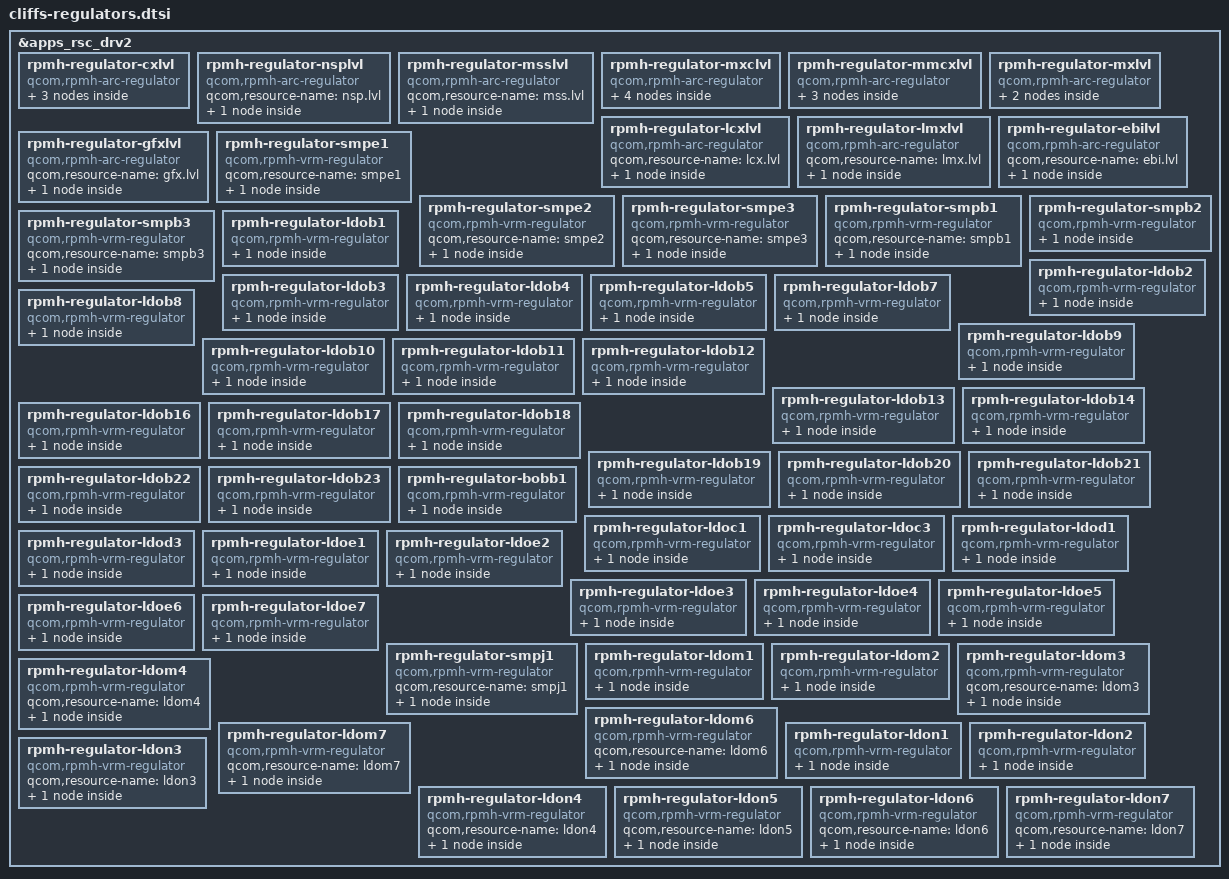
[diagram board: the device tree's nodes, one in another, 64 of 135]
#include <dt-bindings/regulator/qcom,rpmh-regulator-levels.h>

&apps_rsc_drv2 {
	rpmh-regulator-cxlvl {
		compatible = "qcom,rpmh-arc-regulator";
		qcom,resource-name = "cx.lvl";
		proxy-supply = <&VDD_CX_LEVEL>;

		VDD_CX_LEVEL:
		S1C_LEVEL:
		pm_v6c_s1_level: regulator-pm_v6c-s1-level {
			regulator-name = "pm_v6c_s1_level";
			qcom,set = <RPMH_REGULATOR_SET_ALL>;
			regulator-min-microvolt =
				<RPMH_REGULATOR_LEVEL_RETENTION>;
			regulator-max-microvolt = <RPMH_REGULATOR_LEVEL_MAX>;
			qcom,init-voltage-level =
				<RPMH_REGULATOR_LEVEL_TURBO>;
			qcom,proxy-consumer-enable;
			qcom,proxy-consumer-voltage =
				<RPMH_REGULATOR_LEVEL_TURBO
				 RPMH_REGULATOR_LEVEL_MAX>;
		};

		VDD_CX_LEVEL_AO:
		S1C_LEVEL_AO:
		pm_v6c_s1_level_ao: regulator-pm_v6c-s1-level-ao {
			regulator-name = "pm_v6c_s1_level_ao";
			qcom,set = <RPMH_REGULATOR_SET_ACTIVE>;
			regulator-min-microvolt =
				<RPMH_REGULATOR_LEVEL_RETENTION>;
			regulator-max-microvolt = <RPMH_REGULATOR_LEVEL_MAX>;
			qcom,init-voltage-level =
				<RPMH_REGULATOR_LEVEL_RETENTION>;
		};

		VDD_CX_MMCX_SUPPLY_LEVEL: regulator-pm_v6c-s1-mmcx-sup-level {
			regulator-name = "pm_v6c_s1_mmcx_sup_level";
			qcom,set = <RPMH_REGULATOR_SET_ALL>;
			regulator-min-microvolt =
				<RPMH_REGULATOR_LEVEL_MIN_SVS>;
			regulator-max-microvolt =
				<RPMH_REGULATOR_LEVEL_MAX>;
			qcom,init-voltage-level =
				<RPMH_REGULATOR_LEVEL_MIN_SVS>;
		};
	};

	rpmh-regulator-nsplvl {
		compatible = "qcom,rpmh-arc-regulator";
		qcom,resource-name = "nsp.lvl";
		VDD_NSP_LEVEL:
		S2C_LEVEL:
		pm_v6c_s2_level: regulator-pm_v6c-s2-level {
			regulator-name = "pm_v6c_s2_level";
			qcom,set = <RPMH_REGULATOR_SET_ALL>;
			regulator-min-microvolt =
				<RPMH_REGULATOR_LEVEL_RETENTION>;
			regulator-max-microvolt = <RPMH_REGULATOR_LEVEL_MAX>;
			qcom,init-voltage-level =
				<RPMH_REGULATOR_LEVEL_RETENTION>;
		};
	};

	rpmh-regulator-msslvl {
		compatible = "qcom,rpmh-arc-regulator";
		qcom,resource-name = "mss.lvl";
		VDD_MODEM_LEVEL:
		S4C_LEVEL:
		pm_v6c_s4_level: regulator-pm_v6c-s4-level {
			regulator-name = "pm_v6c_s4_level";
			qcom,set = <RPMH_REGULATOR_SET_ALL>;
			regulator-min-microvolt =
				<RPMH_REGULATOR_LEVEL_RETENTION>;
			regulator-max-microvolt = <RPMH_REGULATOR_LEVEL_MAX>;
			qcom,init-voltage-level =
				<RPMH_REGULATOR_LEVEL_RETENTION>;
		};
	};

	rpmh-regulator-mxclvl {
		compatible = "qcom,rpmh-arc-regulator";
		qcom,resource-name = "mxc.lvl";
		proxy-supply = <&VDD_MXC_LEVEL>;

		VDD_MXC_LEVEL:
		S6C_LEVEL:
		pm_v6c_s6_level: regulator-pm_v6c-s6-level {
			regulator-name = "pm_v6c_s6_level";
			qcom,set = <RPMH_REGULATOR_SET_ALL>;
			regulator-min-microvolt =
				<RPMH_REGULATOR_LEVEL_RETENTION>;
			regulator-max-microvolt = <RPMH_REGULATOR_LEVEL_MAX>;
			qcom,init-voltage-level =
				<RPMH_REGULATOR_LEVEL_TURBO>;
			qcom,proxy-consumer-enable;
			qcom,proxy-consumer-voltage =
				<RPMH_REGULATOR_LEVEL_TURBO
				 RPMH_REGULATOR_LEVEL_MAX>;
		};

		VDD_MXC_LEVEL_AO:
		S6C_LEVEL_AO:
		pm_v6c_s6_level_ao: regulator-pm_v6c-s6-level-ao {
			regulator-name = "pm_v6c_s6_level_ao";
			qcom,set = <RPMH_REGULATOR_SET_ACTIVE>;
			regulator-min-microvolt =
				<RPMH_REGULATOR_LEVEL_RETENTION>;
			regulator-max-microvolt = <RPMH_REGULATOR_LEVEL_MAX>;
			qcom,init-voltage-level =
				<RPMH_REGULATOR_LEVEL_RETENTION>;
		};

		VDD_MXC_MMCX_VOTER_LEVEL:
		VDD_MXC_MM_VOTER_LEVEL:
		VDD_MM_MXC_VOTER_LEVEL: regulator-pm_v6c-s6-mmcx-voter-level {
			regulator-name = "pm_v6c_s6_mmcx_voter_level";
			pm_v6c_s6_mmcx_voter_level-parent-supply =
				<&VDD_MMCX_LEVEL>;
			qcom,set = <RPMH_REGULATOR_SET_ALL>;
			regulator-min-microvolt =
				<RPMH_REGULATOR_LEVEL_MIN_SVS>;
			regulator-max-microvolt =
				<RPMH_REGULATOR_LEVEL_MAX>;
			qcom,init-voltage-level =
				<RPMH_REGULATOR_LEVEL_MIN_SVS>;
		};

		VDD_MXC_GFX_VOTER_LEVEL:
		VDD_GFX_MXC_VOTER_LEVEL:
		regulator-pm_v6c-s6-gfx-voter-level {
			regulator-name = "pm_v6c_s6_gfx_voter_level";
			pm_v6c_s6_gfx_voter_level-parent-supply =
				<&VDD_GFX_LEVEL>;
			qcom,set = <RPMH_REGULATOR_SET_ALL>;
			regulator-min-microvolt =
				<RPMH_REGULATOR_LEVEL_MIN_SVS>;
			regulator-max-microvolt =
				<RPMH_REGULATOR_LEVEL_MAX>;
			qcom,init-voltage-level =
				<RPMH_REGULATOR_LEVEL_MIN_SVS>;
		};
	};

	rpmh-regulator-mmcxlvl {
		compatible = "qcom,rpmh-arc-regulator";
		qcom,resource-name = "mmcx.lvl";
		proxy-supply = <&VDD_MMCX_LEVEL>;

		VDD_MMCX_LEVEL:
		VDD_MM_LEVEL:
		S6D_LEVEL:
		pm_v8_s6_level: regulator-pm_v8-s6-level {
			regulator-name = "pm_v8_s6_level";
			qcom,set = <RPMH_REGULATOR_SET_ALL>;
			pm_v8_s6_level-parent-supply =
				<&VDD_CX_MMCX_SUPPLY_LEVEL>;
			regulator-min-microvolt =
				<RPMH_REGULATOR_LEVEL_LOW_SVS_D1>;
			regulator-max-microvolt = <RPMH_REGULATOR_LEVEL_MAX>;
			qcom,init-voltage-level =
				<RPMH_REGULATOR_LEVEL_TURBO>;
			qcom,proxy-consumer-enable;
			qcom,proxy-consumer-voltage =
				<RPMH_REGULATOR_LEVEL_TURBO
				 RPMH_REGULATOR_LEVEL_MAX>;
		};

		VDD_MMCX_LEVEL_AO:
		S6D_LEVEL_AO:
		pm_v8_s6_level_ao: regulator-pm_v8-s6-level-ao {
			regulator-name = "pm_v8_s6_level_ao";
			qcom,set = <RPMH_REGULATOR_SET_ACTIVE>;
			regulator-min-microvolt =
				<RPMH_REGULATOR_LEVEL_LOW_SVS_D1>;
			regulator-max-microvolt = <RPMH_REGULATOR_LEVEL_MAX>;
			qcom,init-voltage-level =
				<RPMH_REGULATOR_LEVEL_LOW_SVS_D1>;
		};

		regulator-pm_v8-s6-level-so {
			regulator-name = "pm_v8_s6_level_so";
			qcom,set = <RPMH_REGULATOR_SET_SLEEP>;
			regulator-min-microvolt =
				<RPMH_REGULATOR_LEVEL_LOW_SVS_D1>;
			regulator-max-microvolt = <RPMH_REGULATOR_LEVEL_MAX>;
			qcom,init-voltage-level =
				<RPMH_REGULATOR_LEVEL_LOW_SVS_D1>;
		};
	};

	rpmh-regulator-mxlvl {
		compatible = "qcom,rpmh-arc-regulator";
		qcom,resource-name = "mx.lvl";
		proxy-supply = <&VDD_MXA_LEVEL>;

		VDD_MXA_LEVEL:
		S8D_LEVEL:
		pm_v8_s8_level: regulator-pm_v8-s8-level {
			regulator-name = "pm_v8_s8_level";
			qcom,set = <RPMH_REGULATOR_SET_ALL>;
			regulator-min-microvolt =
				<RPMH_REGULATOR_LEVEL_RETENTION>;
			regulator-max-microvolt = <RPMH_REGULATOR_LEVEL_MAX>;
			qcom,init-voltage-level =
				<RPMH_REGULATOR_LEVEL_TURBO>;
			qcom,proxy-consumer-enable;
			qcom,proxy-consumer-voltage =
				<RPMH_REGULATOR_LEVEL_TURBO
				 RPMH_REGULATOR_LEVEL_MAX>;
		};

		VDD_MXA_LEVEL_AO:
		S8D_LEVEL_AO:
		pm_v8_s8_level_ao: regulator-pm_v8-s8-level-ao {
			regulator-name = "pm_v8_s8_level_ao";
			qcom,set = <RPMH_REGULATOR_SET_ACTIVE>;
			regulator-min-microvolt =
				<RPMH_REGULATOR_LEVEL_RETENTION>;
			regulator-max-microvolt = <RPMH_REGULATOR_LEVEL_MAX>;
			qcom,init-voltage-level =
				<RPMH_REGULATOR_LEVEL_RETENTION>;
		};
	};

	rpmh-regulator-lcxlvl {
		compatible = "qcom,rpmh-arc-regulator";
		qcom,resource-name = "lcx.lvl";

		VDD_LPI_CX_LEVEL:
		L2D_LEVEL:
		pm_v8_l2_level: regulator-pm_v8-l2-level {
			regulator-name = "pm_v8_l2_level";
			qcom,set = <RPMH_REGULATOR_SET_ALL>;
			regulator-min-microvolt =
				<RPMH_REGULATOR_LEVEL_RETENTION>;
			regulator-max-microvolt = <RPMH_REGULATOR_LEVEL_MAX>;
			qcom,init-voltage-level =
				<RPMH_REGULATOR_LEVEL_RETENTION>;
		};
	};

	rpmh-regulator-lmxlvl {
		compatible = "qcom,rpmh-arc-regulator";
		qcom,resource-name = "lmx.lvl";

		VDD_LPI_MX_LEVEL:
		L2C_LEVEL:
		pm_v6c_l2_level: regulator-pm_v6c-l2-level {
			regulator-name = "pm_v6c_l2_level";
			qcom,set = <RPMH_REGULATOR_SET_ALL>;
			regulator-min-microvolt =
				<RPMH_REGULATOR_LEVEL_RETENTION>;
			regulator-max-microvolt = <RPMH_REGULATOR_LEVEL_MAX>;
			qcom,init-voltage-level =
				<RPMH_REGULATOR_LEVEL_RETENTION>;
		};
	};

	rpmh-regulator-ebilvl {
		compatible = "qcom,rpmh-arc-regulator";
		qcom,resource-name = "ebi.lvl";

		VDD_EBI_LEVEL:
		S1I_LEVEL:
		pmg1110_i_s1_level: regulator-pmg1110-i-s1-level {
			regulator-name = "pmg1110_i_s1_level";
			qcom,set = <RPMH_REGULATOR_SET_ALL>;
			regulator-min-microvolt =
				<RPMH_REGULATOR_LEVEL_RETENTION>;
			regulator-max-microvolt = <RPMH_REGULATOR_LEVEL_MAX>;
			qcom,init-voltage-level =
				<RPMH_REGULATOR_LEVEL_RETENTION>;
		};
	};

	rpmh-regulator-gfxlvl {
		compatible = "qcom,rpmh-arc-regulator";
		qcom,resource-name = "gfx.lvl";

		VDD_GFX_LEVEL:
		S4B_LEVEL:
		pmxr2230_s4_level: regulator-pmxr2230-s4-level {
			regulator-name = "pmxr2230_s4_level";
			qcom,set = <RPMH_REGULATOR_SET_ALL>;
			regulator-min-microvolt =
				<RPMH_REGULATOR_LEVEL_RETENTION>;
			regulator-max-microvolt = <RPMH_REGULATOR_LEVEL_MAX>;
			qcom,init-voltage-level =
				<RPMH_REGULATOR_LEVEL_RETENTION>;
		};
	};

	rpmh-regulator-smpe1 {
		compatible = "qcom,rpmh-vrm-regulator";
		qcom,resource-name = "smpe1";

		S1E:
		pmr735a_s1: regulator-pmr735a-s1 {
			regulator-name = "pmr735a_s1";
			qcom,set = <RPMH_REGULATOR_SET_ALL>;
			regulator-min-microvolt = <1010000>;
			regulator-max-microvolt = <1120000>;
			qcom,init-voltage = <1080000>;
		};
	};

	rpmh-regulator-smpe2 {
		compatible = "qcom,rpmh-vrm-regulator";
		qcom,resource-name = "smpe2";

		S2E:
		pmr735a_s2: regulator-pmr735a-s2 {
			regulator-name = "pmr735a_s2";
			qcom,set = <RPMH_REGULATOR_SET_ALL>;
			regulator-min-microvolt = <300000>;
			regulator-max-microvolt = <570000>;
			qcom,init-voltage = <500000>;
		};
	};

	rpmh-regulator-smpe3 {
		compatible = "qcom,rpmh-vrm-regulator";
		qcom,resource-name = "smpe3";

		S3E:
		pmr735a_s3: regulator-pmr735a-s3 {
			regulator-name = "pmr735a_s3";
			qcom,set = <RPMH_REGULATOR_SET_ALL>;
			regulator-min-microvolt = <1600000>;
			regulator-max-microvolt = <2400000>;
			qcom,init-voltage = <1600000>;
		};
	};

	rpmh-regulator-smpb1 {
		compatible = "qcom,rpmh-vrm-regulator";
		qcom,resource-name = "smpb1";

		S1B:
		pmxr2230_s1: regulator-pmxr2230-s1 {
			regulator-name = "pmxr2230_s1";
			qcom,set = <RPMH_REGULATOR_SET_ALL>;
			regulator-min-microvolt = <1856000>;
			regulator-max-microvolt = <2040000>;
			qcom,init-voltage = <1856000>;
		};
	};

	rpmh-regulator-smpb2 {
		compatible = "qcom,rpmh-vrm-regulator";
		qcom,resource-name = "smpb2";
		qcom,regulator-type = "pmic5-ftsmps";
		qcom,supported-modes = <RPMH_REGULATOR_MODE_RET
			 RPMH_REGULATOR_MODE_HPM>;
		qcom,mode-threshold-currents = <0 200000>;

		S2B:
		pmxr2230_s2: regulator-pmxr2230-s2 {
			regulator-name = "pmxr2230_s2";
			qcom,set = <RPMH_REGULATOR_SET_ALL>;
			regulator-min-microvolt = <1256000>;
			regulator-max-microvolt = <1408000>;
			qcom,init-voltage = <1256000>;
			qcom,init-mode = <RPMH_REGULATOR_MODE_RET>;
		};
	};

	rpmh-regulator-smpb3 {
		compatible = "qcom,rpmh-vrm-regulator";
		qcom,resource-name = "smpb3";

		S3B:
		pmxr2230_s3: regulator-pmxr2230-s3 {
			regulator-name = "pmxr2230_s3";
			qcom,set = <RPMH_REGULATOR_SET_ALL>;
			regulator-min-microvolt = <968000>;
			regulator-max-microvolt = <1040000>;
			qcom,init-voltage = <984000>;
		};
	};

	rpmh-regulator-ldob1 {
		compatible = "qcom,rpmh-vrm-regulator";
		qcom,resource-name = "ldob1";
		qcom,regulator-type = "pmic5-ldo";
		qcom,supported-modes =
			<RPMH_REGULATOR_MODE_LPM
			RPMH_REGULATOR_MODE_HPM>;
		qcom,mode-threshold-currents = <0 30000>;

		L1B:
		pmxr2230_l1: regulator-pmxr2230-l1 {
			regulator-name = "pmxr2230_l1";
			qcom,set = <RPMH_REGULATOR_SET_ALL>;
			regulator-min-microvolt = <880000>;
			regulator-max-microvolt = <958000>;
			qcom,init-voltage = <880000>;
			qcom,init-mode = <RPMH_REGULATOR_MODE_HPM>;
		};
	};

	rpmh-regulator-ldob2 {
		compatible = "qcom,rpmh-vrm-regulator";
		qcom,resource-name = "ldob2";
		qcom,regulator-type = "pmic5-ldo";
		qcom,supported-modes =
			<RPMH_REGULATOR_MODE_LPM
			RPMH_REGULATOR_MODE_HPM>;
		qcom,mode-threshold-currents = <0 30000>;
		proxy-supply = <&pmxr2230_l2>;

		L2B:
		pmxr2230_l2: regulator-pmxr2230-l2 {
			regulator-name = "pmxr2230_l2";
			qcom,set = <RPMH_REGULATOR_SET_ALL>;
			regulator-min-microvolt = <880000>;
			regulator-max-microvolt = <950000>;
			qcom,init-voltage = <880000>;
			qcom,init-mode = <RPMH_REGULATOR_MODE_HPM>;
			qcom,proxy-consumer-enable;
			qcom,supply-enable-load = <98000>;
		};
	};

	rpmh-regulator-ldob3 {
		compatible = "qcom,rpmh-vrm-regulator";
		qcom,resource-name = "ldob3";
		qcom,regulator-type = "pmic5-ldo";
		qcom,supported-modes =
			<RPMH_REGULATOR_MODE_LPM
			RPMH_REGULATOR_MODE_HPM>;
		qcom,mode-threshold-currents = <0 30000>;

		L3B:
		pmxr2230_l3: regulator-pmxr2230-l3 {
			regulator-name = "pmxr2230_l3";
			qcom,set = <RPMH_REGULATOR_SET_ALL>;
			regulator-min-microvolt = <880000>;
			regulator-max-microvolt = <920000>;
			qcom,init-voltage = <880000>;
			qcom,init-mode = <RPMH_REGULATOR_MODE_HPM>;
		};
	};

	rpmh-regulator-ldob4 {
		compatible = "qcom,rpmh-vrm-regulator";
		qcom,resource-name = "ldob4";
		qcom,regulator-type = "pmic5-ldo";
		qcom,supported-modes =
			<RPMH_REGULATOR_MODE_LPM
			RPMH_REGULATOR_MODE_HPM>;
		qcom,mode-threshold-currents = <0 30000>;
		proxy-supply = <&pmxr2230_l4>;

		L4B:
		pmxr2230_l4: regulator-pmxr2230-l4 {
			regulator-name = "pmxr2230_l4";
			qcom,set = <RPMH_REGULATOR_SET_ALL>;
			regulator-min-microvolt = <1200000>;
			regulator-max-microvolt = <1200000>;
			qcom,init-voltage = <1200000>;
			qcom,init-mode = <RPMH_REGULATOR_MODE_HPM>;
			qcom,proxy-consumer-enable;
			qcom,supply-enable-load = <16600>;
		};
	};

	rpmh-regulator-ldob5 {
		compatible = "qcom,rpmh-vrm-regulator";
		qcom,resource-name = "ldob5";
		qcom,regulator-type = "pmic5-ldo";
		qcom,supported-modes =
			<RPMH_REGULATOR_MODE_RET
			RPMH_REGULATOR_MODE_LPM
			RPMH_REGULATOR_MODE_HPM>;
		qcom,mode-threshold-currents = <0 10000 30000>;

		L5B:
		pmxr2230_l5: regulator-pmxr2230-l5 {
			regulator-name = "pmxr2230_l5";
			qcom,set = <RPMH_REGULATOR_SET_ALL>;
			regulator-min-microvolt = <1200000>;
			regulator-max-microvolt = <1200000>;
			qcom,init-voltage = <1200000>;
			qcom,init-mode = <RPMH_REGULATOR_MODE_HPM>;
		};
	};

	rpmh-regulator-ldob7 {
		compatible = "qcom,rpmh-vrm-regulator";
		qcom,resource-name = "ldob7";
		qcom,regulator-type = "pmic5-ldo";
		qcom,supported-modes =
			<RPMH_REGULATOR_MODE_LPM
			RPMH_REGULATOR_MODE_HPM>;
		qcom,mode-threshold-currents = <0 30000>;

		L7B:
		pmxr2230_l7: regulator-pmxr2230-l7 {
			regulator-name = "pmxr2230_l7";
			qcom,set = <RPMH_REGULATOR_SET_ALL>;
			regulator-min-microvolt = <1800000>;
			regulator-max-microvolt = <1800000>;
			qcom,init-voltage = <1800000>;
			qcom,init-mode = <RPMH_REGULATOR_MODE_HPM>;
		};
	};

	rpmh-regulator-ldob8 {
		compatible = "qcom,rpmh-vrm-regulator";
		qcom,resource-name = "ldob8";
		qcom,regulator-type = "pmic5-ldo";
		qcom,supported-modes =
			<RPMH_REGULATOR_MODE_LPM
			RPMH_REGULATOR_MODE_HPM>;
		qcom,mode-threshold-currents = <0 30000>;
		proxy-supply = <&pmxr2230_l8>;

		L8B:
		pmxr2230_l8: regulator-pmxr2230-l8 {
			regulator-name = "pmxr2230_l8";
			qcom,set = <RPMH_REGULATOR_SET_ALL>;
			regulator-min-microvolt = <1800000>;
			regulator-max-microvolt = <1800000>;
			qcom,init-voltage = <1800000>;
			qcom,init-mode = <RPMH_REGULATOR_MODE_HPM>;
			qcom,proxy-consumer-enable;
			qcom,proxy-consumer-current = <220000>;
		};
	};

	rpmh-regulator-ldob9 {
		compatible = "qcom,rpmh-vrm-regulator";
		qcom,resource-name = "ldob9";
		qcom,regulator-type = "pmic5-ldo";
		qcom,supported-modes =
			<RPMH_REGULATOR_MODE_LPM
			RPMH_REGULATOR_MODE_HPM>;
		qcom,mode-threshold-currents = <0 30000>;

		L9B:
		pmxr2230_l9: regulator-pmxr2230-l9 {
			regulator-name = "pmxr2230_l9";
			qcom,set = <RPMH_REGULATOR_SET_ALL>;
			regulator-min-microvolt = <756000>;
			regulator-max-microvolt = <816000>;
			qcom,init-voltage = <756000>;
			qcom,init-mode = <RPMH_REGULATOR_MODE_HPM>;
		};
	};

	rpmh-regulator-ldob10 {
		compatible = "qcom,rpmh-vrm-regulator";
		qcom,resource-name = "ldob10";
		qcom,regulator-type = "pmic5-ldo";
		qcom,supported-modes =
			<RPMH_REGULATOR_MODE_LPM
			RPMH_REGULATOR_MODE_HPM>;
		qcom,mode-threshold-currents = <0 30000>;

		L10B:
		pmxr2230_l10: regulator-pmxr2230-l10 {
			regulator-name = "pmxr2230_l10";
			qcom,set = <RPMH_REGULATOR_SET_ALL>;
			regulator-min-microvolt = <866000>;
			regulator-max-microvolt = <931000>;
			qcom,init-voltage = <866000>;
			qcom,init-mode = <RPMH_REGULATOR_MODE_HPM>;
		};
	};

	rpmh-regulator-ldob11 {
		compatible = "qcom,rpmh-vrm-regulator";
		qcom,resource-name = "ldob11";
		qcom,regulator-type = "pmic5-ldo";
		qcom,supported-modes =
			<RPMH_REGULATOR_MODE_LPM
			RPMH_REGULATOR_MODE_HPM>;
		qcom,mode-threshold-currents = <0 30000>;

		L11B:
		pmxr2230_l11: regulator-pmxr2230-l11 {
			regulator-name = "pmxr2230_l11";
			qcom,set = <RPMH_REGULATOR_SET_ALL>;
			regulator-min-microvolt = <1800000>;
			regulator-max-microvolt = <1800000>;
			qcom,init-voltage = <1800000>;
			qcom,init-mode = <RPMH_REGULATOR_MODE_HPM>;
		};
	};

	rpmh-regulator-ldob12 {
		compatible = "qcom,rpmh-vrm-regulator";
		qcom,resource-name = "ldob12";
		qcom,regulator-type = "pmic5-ldo";
		qcom,supported-modes =
			<RPMH_REGULATOR_MODE_LPM
			RPMH_REGULATOR_MODE_HPM>;
		qcom,mode-threshold-currents = <0 10000>;

		L12B:
		pmxr2230_l12: regulator-pmxr2230-l12 {
			regulator-name = "pmxr2230_l12";
			qcom,set = <RPMH_REGULATOR_SET_ALL>;
			qcom,init-mode = <RPMH_REGULATOR_MODE_HPM>;
			/*
			 * Remove min/max voltages for this regulator as initial
			 * voltage of  L12B is set to be 2.4v/2.96v during PON
			 * depending upon the UFS mode. UFS is the only client
			 * on this and this regulator will only be voted
			 * for enabling/disabling conditions.
			 */
		};
	};

	rpmh-regulator-ldob13 {
		compatible = "qcom,rpmh-vrm-regulator";
		qcom,resource-name = "ldob13";
		qcom,regulator-type = "pmic5-ldo";
		qcom,supported-modes =
			<RPMH_REGULATOR_MODE_LPM
			RPMH_REGULATOR_MODE_HPM>;
		qcom,mode-threshold-currents = <0 10000>;

		L13B:
		pmxr2230_l13: regulator-pmxr2230-l13 {
			regulator-name = "pmxr2230_l13";
			qcom,set = <RPMH_REGULATOR_SET_ALL>;
			regulator-min-microvolt = <2700000>;
			regulator-max-microvolt = <3300000>;
			qcom,init-voltage = <2700000>;
			qcom,init-mode = <RPMH_REGULATOR_MODE_HPM>;
		};
	};

	rpmh-regulator-ldob14 {
		compatible = "qcom,rpmh-vrm-regulator";
		qcom,resource-name = "ldob14";
		qcom,regulator-type = "pmic5-ldo";
		qcom,supported-modes =
			<RPMH_REGULATOR_MODE_LPM
			RPMH_REGULATOR_MODE_HPM>;
		qcom,mode-threshold-currents = <0 10000>;

		L14B:
		pmxr2230_l14: regulator-pmxr2230-l14 {
			regulator-name = "pmxr2230_l14";
			qcom,set = <RPMH_REGULATOR_SET_ALL>;
			regulator-min-microvolt = <2700000>;
			regulator-max-microvolt = <3300000>;
			qcom,init-voltage = <2700000>;
			qcom,init-mode = <RPMH_REGULATOR_MODE_HPM>;
		};
	};

	rpmh-regulator-ldob16 {
		compatible = "qcom,rpmh-vrm-regulator";
		qcom,resource-name = "ldob16";
		qcom,regulator-type = "pmic5-ldo";
		qcom,supported-modes =
			<RPMH_REGULATOR_MODE_LPM
			RPMH_REGULATOR_MODE_HPM>;
		qcom,mode-threshold-currents = <0 10000>;

		L16B:
		pmxr2230_l16: regulator-pmxr2230-l16 {
			regulator-name = "pmxr2230_l16";
			qcom,set = <RPMH_REGULATOR_SET_ALL>;
			regulator-min-microvolt = <2900000>;
			regulator-max-microvolt = <3544000>;
			qcom,init-voltage = <2900000>;
			qcom,init-mode = <RPMH_REGULATOR_MODE_HPM>;
		};
	};

	rpmh-regulator-ldob17 {
		compatible = "qcom,rpmh-vrm-regulator";
		qcom,resource-name = "ldob17";
		qcom,regulator-type = "pmic5-ldo";
		qcom,supported-modes =
			<RPMH_REGULATOR_MODE_LPM
			RPMH_REGULATOR_MODE_HPM>;
		qcom,mode-threshold-currents = <0 10000>;

		L17B:
		pmxr2230_l17: regulator-pmxr2230-l17 {
			regulator-name = "pmxr2230_l17";
			qcom,set = <RPMH_REGULATOR_SET_ALL>;
			regulator-min-microvolt = <2700000>;
			regulator-max-microvolt = <3300000>;
			qcom,init-voltage = <3104000>;
			qcom,init-mode = <RPMH_REGULATOR_MODE_HPM>;
		};
	};

	rpmh-regulator-ldob18 {
		compatible = "qcom,rpmh-vrm-regulator";
		qcom,resource-name = "ldob18";
		qcom,regulator-type = "pmic5-ldo";
		qcom,supported-modes =
			<RPMH_REGULATOR_MODE_LPM
			RPMH_REGULATOR_MODE_HPM>;
		qcom,mode-threshold-currents = <0 10000>;

		L18B:
		pmxr2230_l18: regulator-pmxr2230-l18 {
			regulator-name = "pmxr2230_l18";
			qcom,set = <RPMH_REGULATOR_SET_ALL>;
			regulator-min-microvolt = <2000000>;
			regulator-max-microvolt = <3000000>;
			qcom,init-voltage = <2000000>;
			qcom,init-mode = <RPMH_REGULATOR_MODE_HPM>;
		};
	};

	rpmh-regulator-ldob19 {
		compatible = "qcom,rpmh-vrm-regulator";
		qcom,resource-name = "ldob19";
		qcom,regulator-type = "pmic5-ldo";
		qcom,supported-modes =
			<RPMH_REGULATOR_MODE_LPM
			RPMH_REGULATOR_MODE_HPM>;
		qcom,mode-threshold-currents = <0 10000>;
		proxy-supply = <&pmxr2230_l19>;

		L19B:
		pmxr2230_l19: regulator-pmxr2230-l19 {
			regulator-name = "pmxr2230_l19";
			qcom,set = <RPMH_REGULATOR_SET_ALL>;
			regulator-min-microvolt = <2600000>;
			regulator-max-microvolt = <3544000>;
			qcom,init-voltage = <2600000>;
			qcom,init-mode = <RPMH_REGULATOR_MODE_HPM>;
			qcom,proxy-consumer-enable;
			qcom,proxy-consumer-current = <10000>;

		};
	};

	rpmh-regulator-ldob20 {
		compatible = "qcom,rpmh-vrm-regulator";
		qcom,resource-name = "ldob20";
		qcom,regulator-type = "pmic5-ldo";
		qcom,supported-modes =
			<RPMH_REGULATOR_MODE_LPM
			RPMH_REGULATOR_MODE_HPM>;
		qcom,mode-threshold-currents = <0 10000>;

		L20B:
		pmxr2230_l20: regulator-pmxr2230-l20 {
			regulator-name = "pmxr2230_l20";
			qcom,set = <RPMH_REGULATOR_SET_ALL>;
			regulator-min-microvolt = <1620000>;
			regulator-max-microvolt = <3544000>;
			qcom,init-voltage = <1620000>;
			qcom,init-mode = <RPMH_REGULATOR_MODE_HPM>;
		};
	};

	rpmh-regulator-ldob21 {
		compatible = "qcom,rpmh-vrm-regulator";
		qcom,resource-name = "ldob21";
		qcom,regulator-type = "pmic5-ldo";
		qcom,supported-modes =
			<RPMH_REGULATOR_MODE_LPM
			RPMH_REGULATOR_MODE_HPM>;
		qcom,mode-threshold-currents = <0 10000>;

		L21B:
		pmxr2230_l21: regulator-pmxr2230-l21 {
			regulator-name = "pmxr2230_l21";
			qcom,set = <RPMH_REGULATOR_SET_ALL>;
			regulator-min-microvolt = <1620000>;
			regulator-max-microvolt = <3544000>;
			qcom,init-voltage = <1620000>;
			qcom,init-mode = <RPMH_REGULATOR_MODE_HPM>;
		};
	};

	rpmh-regulator-ldob22 {
		compatible = "qcom,rpmh-vrm-regulator";
		qcom,resource-name = "ldob22";
		qcom,regulator-type = "pmic5-ldo";
		qcom,supported-modes =
			<RPMH_REGULATOR_MODE_LPM
			RPMH_REGULATOR_MODE_HPM>;
		qcom,mode-threshold-currents = <0 10000>;

		L22B:
		pmxr2230_l22: regulator-pmxr2230-l22 {
			regulator-name = "pmxr2230_l22";
			qcom,set = <RPMH_REGULATOR_SET_ALL>;
			regulator-min-microvolt = <2700000>;
			regulator-max-microvolt = <3400000>;
			qcom,init-voltage = <2700000>;
			qcom,init-mode = <RPMH_REGULATOR_MODE_HPM>;
		};
	};

	rpmh-regulator-ldob23 {
		compatible = "qcom,rpmh-vrm-regulator";
		qcom,resource-name = "ldob23";
		qcom,regulator-type = "pmic5-ldo";
		qcom,supported-modes =
			<RPMH_REGULATOR_MODE_LPM
			RPMH_REGULATOR_MODE_HPM>;
		qcom,mode-threshold-currents = <0 10000>;

		L23B:
		pmxr2230_l23: regulator-pmxr2230-l23 {
			regulator-name = "pmxr2230_l23";
			qcom,set = <RPMH_REGULATOR_SET_ALL>;
			regulator-min-microvolt = <1650000>;
			regulator-max-microvolt = <3544000>;
			qcom,init-voltage = <1650000>;
			qcom,init-mode = <RPMH_REGULATOR_MODE_HPM>;
		};
	};

	rpmh-regulator-bobb1 {
		compatible = "qcom,rpmh-vrm-regulator";
		qcom,resource-name = "bobb1";
		qcom,regulator-type = "pmic5-bob";
		qcom,supported-modes =
			<RPMH_REGULATOR_MODE_PASS
			RPMH_REGULATOR_MODE_AUTO
			RPMH_REGULATOR_MODE_HPM>;
		qcom,mode-threshold-currents = <0 1000000 2000000>;

		BOB:
		pmxr2230_bob: regulator-pmxr2230-bob1 {
			regulator-name = "pmxr2230_bob";
			qcom,set = <RPMH_REGULATOR_SET_ALL>;
			regulator-min-microvolt = <3008000>;
			regulator-max-microvolt = <3960000>;
			qcom,init-voltage = <3296000>;
			qcom,init-mode = <RPMH_REGULATOR_MODE_PASS>;
		};
	};

	rpmh-regulator-ldoc1 {
		compatible = "qcom,rpmh-vrm-regulator";
		qcom,resource-name = "ldoc1";
		qcom,regulator-type = "pmic5-ldo";
		qcom,supported-modes =
			<RPMH_REGULATOR_MODE_LPM
			RPMH_REGULATOR_MODE_HPM>;
		qcom,mode-threshold-currents = <0 30000>;

		L1C:
		pm_v6c_l1: regulator-pm_v6c-l1 {
			regulator-name = "pm_v6c_l1";
			qcom,set = <RPMH_REGULATOR_SET_ALL>;
			regulator-min-microvolt = <904000>;
			regulator-max-microvolt = <970000>;
			qcom,init-voltage = <904000>;
			qcom,init-mode = <RPMH_REGULATOR_MODE_HPM>;
		};
	};

	rpmh-regulator-ldoc3 {
		compatible = "qcom,rpmh-vrm-regulator";
		qcom,resource-name = "ldoc3";
		qcom,regulator-type = "pmic5-ldo";
		qcom,supported-modes =
			<RPMH_REGULATOR_MODE_LPM
			RPMH_REGULATOR_MODE_HPM>;
		qcom,mode-threshold-currents = <0 30000>;
		proxy-supply = <&pm_v6c_l3>;

		L3C:
		pm_v6c_l3: regulator-pm_v6c-l3 {
			regulator-name = "pm_v6c_l3";
			qcom,set = <RPMH_REGULATOR_SET_ALL>;
			regulator-min-microvolt = <1200000>;
			regulator-max-microvolt = <1250000>;
			qcom,init-voltage = <1200000>;
			qcom,init-mode = <RPMH_REGULATOR_MODE_HPM>;
			qcom,proxy-consumer-enable;
			qcom,proxy-consumer-current = <200000>;
		};
	};

	rpmh-regulator-ldod1 {
		compatible = "qcom,rpmh-vrm-regulator";
		qcom,resource-name = "ldod1";
		qcom,regulator-type = "pmic5-ldo";
		qcom,supported-modes =
			<RPMH_REGULATOR_MODE_LPM
			RPMH_REGULATOR_MODE_HPM>;
		qcom,mode-threshold-currents = <0 30000>;

		L1D:
		pm_v8_l1: regulator-pm_v8-l1 {
			regulator-name = "pm_v8_l1";
			qcom,set = <RPMH_REGULATOR_SET_ALL>;
			regulator-min-microvolt = <866000>;
			regulator-max-microvolt = <958000>;
			qcom,init-voltage = <912000>;
			qcom,init-mode = <RPMH_REGULATOR_MODE_HPM>;
		};
	};

	rpmh-regulator-ldod3 {
		compatible = "qcom,rpmh-vrm-regulator";
		qcom,resource-name = "ldod3";
		qcom,regulator-type = "pmic5-ldo";
		qcom,supported-modes =
			<RPMH_REGULATOR_MODE_LPM
			RPMH_REGULATOR_MODE_HPM>;
		qcom,mode-threshold-currents = <0 30000>;
		proxy-supply = <&pm_v8_l3>;

		L3D:
		pm_v8_l3: regulator-pm_v8-l3 {
			regulator-name = "pm_v8_l3";
			qcom,set = <RPMH_REGULATOR_SET_ALL>;
			regulator-min-microvolt = <1140000>;
			regulator-max-microvolt = <1260000>;
			qcom,init-voltage = <1200000>;
			qcom,init-mode = <RPMH_REGULATOR_MODE_HPM>;
			qcom,proxy-consumer-enable;
			qcom,proxy-consumer-current = <31000>;
		};
	};

	rpmh-regulator-ldoe1 {
		compatible = "qcom,rpmh-vrm-regulator";
		qcom,resource-name = "ldoe1";
		qcom,regulator-type = "pmic5-ldo";
		qcom,supported-modes =
			<RPMH_REGULATOR_MODE_LPM
			RPMH_REGULATOR_MODE_HPM>;
		qcom,mode-threshold-currents = <0 30000>;

		L1E:
		pmr735a_l1: regulator-pmr735a-l1 {
			regulator-name = "pmr735a_l1";
			qcom,set = <RPMH_REGULATOR_SET_ALL>;
			regulator-min-microvolt = <488000>;
			regulator-max-microvolt = <912000>;
			qcom,init-voltage = <488000>;
			qcom,init-mode = <RPMH_REGULATOR_MODE_HPM>;
		};
	};

	rpmh-regulator-ldoe2 {
		compatible = "qcom,rpmh-vrm-regulator";
		qcom,resource-name = "ldoe2";
		qcom,regulator-type = "pmic5-ldo";
		qcom,supported-modes =
			<RPMH_REGULATOR_MODE_LPM
			RPMH_REGULATOR_MODE_HPM>;
		qcom,mode-threshold-currents = <0 30000>;

		L2E:
		pmr735a_l2: regulator-pmr735a-l2 {
			regulator-name = "pmr735a_l2";
			qcom,set = <RPMH_REGULATOR_SET_ALL>;
			regulator-min-microvolt = <920000>;
			regulator-max-microvolt = <969000>;
			qcom,init-voltage = <920000>;
			qcom,init-mode = <RPMH_REGULATOR_MODE_HPM>;
		};
	};

	rpmh-regulator-ldoe3 {
		compatible = "qcom,rpmh-vrm-regulator";
		qcom,resource-name = "ldoe3";
		qcom,regulator-type = "pmic5-ldo";
		qcom,supported-modes =
			<RPMH_REGULATOR_MODE_LPM
			RPMH_REGULATOR_MODE_HPM>;
		qcom,mode-threshold-currents = <0 30000>;

		L3E:
		pmr735a_l3: regulator-pmr735a-l3 {
			regulator-name = "pmr735a_l3";
			qcom,set = <RPMH_REGULATOR_SET_ALL>;
			regulator-min-microvolt = <504000>;
			regulator-max-microvolt = <868000>;
			qcom,init-voltage = <504000>;
			qcom,init-mode = <RPMH_REGULATOR_MODE_HPM>;
		};
	};

	rpmh-regulator-ldoe4 {
		compatible = "qcom,rpmh-vrm-regulator";
		qcom,resource-name = "ldoe4";
		qcom,regulator-type = "pmic5-ldo";
		qcom,supported-modes =
			<RPMH_REGULATOR_MODE_LPM
			RPMH_REGULATOR_MODE_HPM>;
		qcom,mode-threshold-currents = <0 10000>;

		L4E:
		pmr735a_l4: regulator-pmr735a-l4 {
			regulator-name = "pmr735a_l4";
			qcom,set = <RPMH_REGULATOR_SET_ALL>;
			regulator-min-microvolt = <1620000>;
			regulator-max-microvolt = <2000000>;
			qcom,init-voltage = <1620000>;
			qcom,init-mode = <RPMH_REGULATOR_MODE_HPM>;
		};
	};

	rpmh-regulator-ldoe5 {
		compatible = "qcom,rpmh-vrm-regulator";
		qcom,resource-name = "ldoe5";
		qcom,regulator-type = "pmic5-ldo";
		qcom,supported-modes =
			<RPMH_REGULATOR_MODE_LPM
			RPMH_REGULATOR_MODE_HPM>;
		qcom,mode-threshold-currents = <0 30000>;

		L5E:
		pmr735a_l5: regulator-pmr735a-l5 {
			regulator-name = "pmr735a_l5";
			qcom,set = <RPMH_REGULATOR_SET_ALL>;
			regulator-min-microvolt = <1100000>;
			regulator-max-microvolt = <1304000>;
			qcom,init-voltage = <1200000>;
			qcom,init-mode = <RPMH_REGULATOR_MODE_HPM>;
		};
	};

	rpmh-regulator-ldoe6 {
		compatible = "qcom,rpmh-vrm-regulator";
		qcom,resource-name = "ldoe6";
		qcom,regulator-type = "pmic5-ldo";
		qcom,supported-modes =
			<RPMH_REGULATOR_MODE_LPM
			RPMH_REGULATOR_MODE_HPM>;
		qcom,mode-threshold-currents = <0 30000>;

		L6E:
		pmr735a_l6: regulator-pmr735a-l6 {
			regulator-name = "pmr735a_l6";
			qcom,set = <RPMH_REGULATOR_SET_ALL>;
			regulator-min-microvolt = <1080000>;
			regulator-max-microvolt = <1304000>;
			qcom,init-voltage = <1080000>;
			qcom,init-mode = <RPMH_REGULATOR_MODE_HPM>;
		};
	};

	rpmh-regulator-ldoe7 {
		compatible = "qcom,rpmh-vrm-regulator";
		qcom,resource-name = "ldoe7";
		qcom,regulator-type = "pmic5-ldo";
		qcom,supported-modes =
			<RPMH_REGULATOR_MODE_LPM
			RPMH_REGULATOR_MODE_HPM>;
		qcom,mode-threshold-currents = <0 10000>;

		L7E:
		pmr735a_l7: regulator-pmr735a-l7 {
			regulator-name = "pmr735a_l7";
			qcom,set = <RPMH_REGULATOR_SET_ALL>;
			regulator-min-microvolt = <1620000>;
			regulator-max-microvolt = <3300000>;
			qcom,init-voltage = <1620000>;
			qcom,init-mode = <RPMH_REGULATOR_MODE_HPM>;
		};
	};

	rpmh-regulator-smpj1 {
		compatible = "qcom,rpmh-vrm-regulator";
		qcom,resource-name = "smpj1";

		S1J:
		pmg1110_j_s1: regulator-pmg1110-j-s1 {
			regulator-name = "pmg1110_j_s1";
			qcom,set = <RPMH_REGULATOR_SET_ALL>;
			regulator-min-microvolt = <504000>;
			regulator-max-microvolt = <868000>;
			qcom,init-voltage = <504000>;
		};
	};

	rpmh-regulator-ldom1 {
		compatible = "qcom,rpmh-vrm-regulator";
		qcom,resource-name = "ldom1";
		qcom,regulator-type = "pmic5-ldo";
		qcom,supported-modes =
			<RPMH_REGULATOR_MODE_LPM
			RPMH_REGULATOR_MODE_HPM>;
		qcom,mode-threshold-currents = <0 30000>;

		L1M:
		pm8010m_l1: regulator-pm8010m-l1 {
			regulator-name = "pm8010m_l1";
			qcom,set = <RPMH_REGULATOR_SET_ALL>;
			regulator-min-microvolt = <1104000>;
			regulator-max-microvolt = <1104000>;
			qcom,init-voltage = <1104000>;
			qcom,init-mode = <RPMH_REGULATOR_MODE_HPM>;
		};
	};

	rpmh-regulator-ldom2 {
		compatible = "qcom,rpmh-vrm-regulator";
		qcom,resource-name = "ldom2";
		qcom,regulator-type = "pmic5-ldo";
		qcom,supported-modes =
			<RPMH_REGULATOR_MODE_LPM
			RPMH_REGULATOR_MODE_HPM>;
		qcom,mode-threshold-currents = <0 30000>;

		L2M:
		pm8010m_l2: regulator-pm8010m-l2 {
			regulator-name = "pm8010m_l2";
			qcom,set = <RPMH_REGULATOR_SET_ALL>;
			regulator-min-microvolt = <1056000>;
			regulator-max-microvolt = <1056000>;
			qcom,init-voltage = <1056000>;
			qcom,init-mode = <RPMH_REGULATOR_MODE_HPM>;
		};
	};

	rpmh-regulator-ldom3 {
		compatible = "qcom,rpmh-vrm-regulator";
		qcom,resource-name = "ldom3";

		L3M:
		pm8010m_l3: regulator-pm8010m-l3 {
			regulator-name = "pm8010m_l3";
			qcom,set = <RPMH_REGULATOR_SET_ALL>;
			regulator-min-microvolt = <2800000>;
			regulator-max-microvolt = <2800000>;
			qcom,init-voltage = <2800000>;
		};
	};

	rpmh-regulator-ldom4 {
		compatible = "qcom,rpmh-vrm-regulator";
		qcom,resource-name = "ldom4";

		L4M:
		pm8010m_l4: regulator-pm8010m-l4 {
			regulator-name = "pm8010m_l4";
			qcom,set = <RPMH_REGULATOR_SET_ALL>;
			regulator-min-microvolt = <2800000>;
			regulator-max-microvolt = <2800000>;
			qcom,init-voltage = <2800000>;
		};
	};

	rpmh-regulator-ldom6 {
		compatible = "qcom,rpmh-vrm-regulator";
		qcom,resource-name = "ldom6";

		L6M:
		pm8010m_l6: regulator-pm8010m-l6 {
			regulator-name = "pm8010m_l6";
			qcom,set = <RPMH_REGULATOR_SET_ALL>;
			regulator-min-microvolt = <2800000>;
			regulator-max-microvolt = <2800000>;
			qcom,init-voltage = <2800000>;
		};
	};

	rpmh-regulator-ldom7 {
		compatible = "qcom,rpmh-vrm-regulator";
		qcom,resource-name = "ldom7";

		L7M:
		pm8010m_l7: regulator-pm8010m-l7 {
			regulator-name = "pm8010m_l7";
			qcom,set = <RPMH_REGULATOR_SET_ALL>;
			regulator-min-microvolt = <2800000>;
			regulator-max-microvolt = <2800000>;
			qcom,init-voltage = <2800000>;
		};
	};

	rpmh-regulator-ldon1 {
		compatible = "qcom,rpmh-vrm-regulator";
		qcom,resource-name = "ldon1";
		qcom,regulator-type = "pmic5-ldo";
		qcom,supported-modes =
			<RPMH_REGULATOR_MODE_LPM
			RPMH_REGULATOR_MODE_HPM>;
		qcom,mode-threshold-currents = <0 30000>;

		L1N:
		pm8010n_l1: regulator-pm8010n-l1 {
			regulator-name = "pm8010n_l1";
			qcom,set = <RPMH_REGULATOR_SET_ALL>;
			regulator-min-microvolt = <1104000>;
			regulator-max-microvolt = <1104000>;
			qcom,init-voltage = <1104000>;
			qcom,init-mode = <RPMH_REGULATOR_MODE_HPM>;
		};
	};

	rpmh-regulator-ldon2 {
		compatible = "qcom,rpmh-vrm-regulator";
		qcom,resource-name = "ldon2";
		qcom,regulator-type = "pmic5-ldo";
		qcom,supported-modes =
			<RPMH_REGULATOR_MODE_LPM
			RPMH_REGULATOR_MODE_HPM>;
		qcom,mode-threshold-currents = <0 30000>;

		L2N:
		pm8010n_l2: regulator-pm8010n-l2 {
			regulator-name = "pm8010n_l2";
			qcom,set = <RPMH_REGULATOR_SET_ALL>;
			regulator-min-microvolt = <1056000>;
			regulator-max-microvolt = <1056000>;
			qcom,init-voltage = <1056000>;
			qcom,init-mode = <RPMH_REGULATOR_MODE_HPM>;
		};
	};

	rpmh-regulator-ldon3 {
		compatible = "qcom,rpmh-vrm-regulator";
		qcom,resource-name = "ldon3";

		L3N:
		pm8010n_l3: regulator-pm8010n-l3 {
			regulator-name = "pm8010n_l3";
			qcom,set = <RPMH_REGULATOR_SET_ALL>;
			regulator-min-microvolt = <1800000>;
			regulator-max-microvolt = <1800000>;
			qcom,init-voltage = <1800000>;
		};
	};

	rpmh-regulator-ldon4 {
		compatible = "qcom,rpmh-vrm-regulator";
		qcom,resource-name = "ldon4";

		L4N:
		pm8010n_l4: regulator-pm8010n-l4 {
			regulator-name = "pm8010n_l4";
			qcom,set = <RPMH_REGULATOR_SET_ALL>;
			regulator-min-microvolt = <1800000>;
			regulator-max-microvolt = <1800000>;
			qcom,init-voltage = <1800000>;
		};
	};

	rpmh-regulator-ldon5 {
		compatible = "qcom,rpmh-vrm-regulator";
		qcom,resource-name = "ldon5";

		L5N:
		pm8010n_l5: regulator-pm8010n-l5 {
			regulator-name = "pm8010n_l5";
			qcom,set = <RPMH_REGULATOR_SET_ALL>;
			regulator-min-microvolt = <1800000>;
			regulator-max-microvolt = <1800000>;
			qcom,init-voltage = <1800000>;
		};
	};

	rpmh-regulator-ldon6 {
		compatible = "qcom,rpmh-vrm-regulator";
		qcom,resource-name = "ldon6";

		L6N:
		pm8010n_l6: regulator-pm8010n-l6 {
			regulator-name = "pm8010n_l6";
			qcom,set = <RPMH_REGULATOR_SET_ALL>;
			regulator-min-microvolt = <2800000>;
			regulator-max-microvolt = <2800000>;
			qcom,init-voltage = <2800000>;
		};
	};

	rpmh-regulator-ldon7 {
		compatible = "qcom,rpmh-vrm-regulator";
		qcom,resource-name = "ldon7";

		L7N:
		pm8010n_l7: regulator-pm8010n-l7 {
			regulator-name = "pm8010n_l7";
			qcom,set = <RPMH_REGULATOR_SET_ALL>;
			regulator-min-microvolt = <3304000>;
			regulator-max-microvolt = <3304000>;
			qcom,init-voltage = <3304000>;
		};
	};

};
